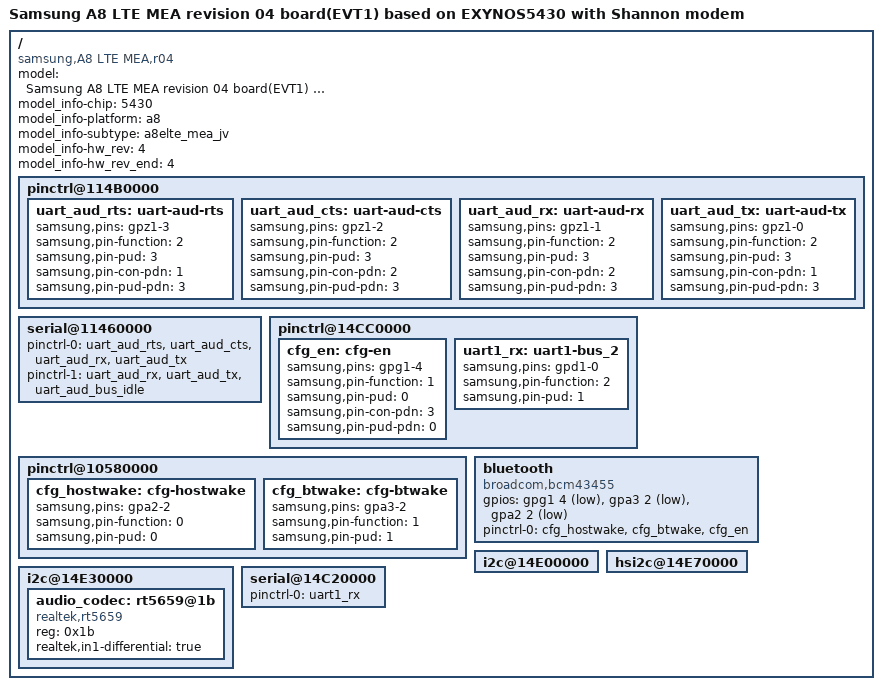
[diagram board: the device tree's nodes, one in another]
/*
 * SAMSUNG UNIVERSAL5430 board device tree source
 *
 * Copyright (c) 2013 Samsung Electronics Co., Ltd.
 *		http://www.samsung.com
 *
 * This program is free software; you can redistribute it and/or modify
 * it under the terms of the GNU General Public License version 2 as
 * published by the Free Software Foundation.
*/

/dts-v1/;
#include "exynos5430-a8_common.dtsi"
#include "exynos5430-a8_battery.dtsi"
#include "exynos5430-a8_gpio_02.dtsi"
#include "exynos5430-a8-modem-ss333-ds.dtsi"
#include "exynos5430-a8e_fingerprint-sensor_00.dtsi"
#include "exynos5430-a8_codec-realtek.dtsi"

/ {
	model = "Samsung A8 LTE MEA revision 04 board(EVT1) based on EXYNOS5430 with Shannon modem";
	model_info-chip = <5430>;
	model_info-platform = "a8";
	model_info-subtype = "a8elte_mea_jv";
	model_info-hw_rev = <4>;
	model_info-hw_rev_end = <4>; /* If add new dts file for new hw , it is set to <x>. x is suppored max system revision by this dts */
	compatible = "samsung,A8 LTE MEA,r04", "samsung,exynos5430";

	pinctrl@114B0000 {
		uart_aud_rts: uart-aud-rts {
			samsung,pins = "gpz1-3";
			samsung,pin-function = <2>;
			samsung,pin-pud = <3>;
			samsung,pin-con-pdn = <1>;
			samsung,pin-pud-pdn = <3>;
		};

		uart_aud_cts: uart-aud-cts {
			samsung,pins = "gpz1-2";
			samsung,pin-function = <2>;
			samsung,pin-pud = <3>;
			samsung,pin-con-pdn = <2>;
			samsung,pin-pud-pdn = <3>;
		};

		uart_aud_rx: uart-aud-rx {
			samsung,pins = "gpz1-1";
			samsung,pin-function = <2>;
			samsung,pin-pud = <3>;
			samsung,pin-con-pdn = <2>;
			samsung,pin-pud-pdn = <3>;
		};

		uart_aud_tx: uart-aud-tx {
			samsung,pins = "gpz1-0";
			samsung,pin-function = <2>;
			samsung,pin-pud = <3>;
			samsung,pin-con-pdn = <1>;
			samsung,pin-pud-pdn = <3>;
		};
	};

	serial@11460000 {
		pinctrl-0 = <&uart_aud_rts &uart_aud_cts &uart_aud_rx &uart_aud_tx>;
		pinctrl-1 = <&uart_aud_rx &uart_aud_tx &uart_aud_bus_idle>;
	};

	pinctrl@14CC0000 {
		cfg_en: cfg-en {
			samsung,pins ="gpg1-4";
			samsung,pin-function = <1>;
			samsung,pin-pud = <0>;
			samsung,pin-con-pdn = <3>;
			samsung,pin-pud-pdn = <0>;
		};
	};

	pinctrl@10580000{
		cfg_hostwake: cfg-hostwake {
			samsung,pins = "gpa2-2";
			samsung,pin-function = <0>;
			samsung,pin-pud = <0>;
		};

		cfg_btwake: cfg-btwake {
			samsung,pins = "gpa3-2";
			samsung,pin-function = <1>;
			samsung,pin-pud = <1>;
		};
	};

	bluetooth {
		compatible = "broadcom,bcm43455";

		gpios = <&gpg1 4 1	/*BT_EN*/
				&gpa3 2 1	/*BT_WAKE*/
				&gpa2 2 0xF	/*BT_HOST_WAKE*/ >;

		pinctrl-names = "default";
		pinctrl-0=<&cfg_hostwake &cfg_btwake &cfg_en>;
		status = "okay";
	};

	i2c@14E00000 {
		/delete-node/ sec-nfc@27;
	};

	hsi2c@14E70000 {
		/delete-node/ es325@3e;
	};
	
	i2c@14E30000 {
		audio_codec: rt5659@1b {
			compatible = "realtek,rt5659";
			reg = <0x1b>;
			realtek,in1-differential = "true";
		};
	};

	serial@14C20000 {
		pinctrl-0 = <&uart1_rx>;
	};

	pinctrl@14CC0000 {
		uart1_rx: uart1-bus_2 {
			samsung,pins = "gpd1-0";
			samsung,pin-function = <2>;
			samsung,pin-pud = <1>;
		};
	};
};
